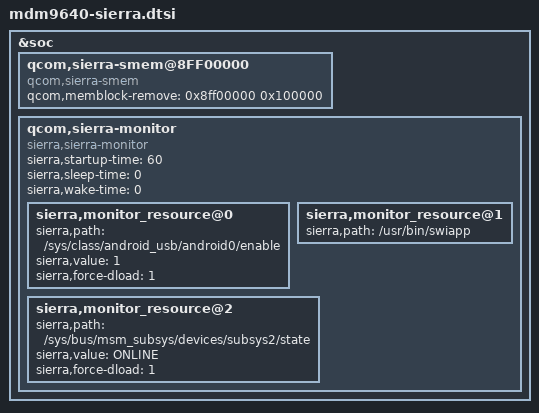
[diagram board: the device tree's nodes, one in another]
/* Copyright (c) 2015, Sierra Wireless, Inc. All rights reserved.
 *
 * This program is free software; you can redistribute it and/or modify
 * it under the terms of the GNU General Public License version 2 and
 * only version 2 as published by the Free Software Foundation.
 *
 * This program is distributed in the hope that it will be useful,
 * but WITHOUT ANY WARRANTY; without even the implied warranty of
 * MERCHANTABILITY or FITNESS FOR A PARTICULAR PURPOSE.  See the
 * GNU General Public License for more details.
 */

&soc {
/* Sierra shared memory
 *
 * A section of memory at the top of DDR is reserved for Sierra
 * boot-app messages, crash information, and other data.  This section
 * is non-initialized in order to preserve data across reboots.  The
 * size and base are (unfortunately) defined in multiple places.
 * 
 * WARNING:  These definitions must be kept in sync
 *
 * boot_images/build/ms/9x45.target.builds
 * modem_proc/config/9645/cust_config.xml
 * modem_proc/sierra/bs/api/bsaddress.h
 * apps_proc/kernel/arch/arm/mach-msm/include/mach/sierra_smem.h
 * apps_proc/kernel/arch/arm/boot/dts/qcom/mdm9640.dtsi
 */
	qcom,sierra-smem@8FF00000 {
		compatible = "qcom,sierra-smem";
		qcom,memblock-remove = <0x8ff00000 0x100000>;
	};


	qcom,sierra-monitor {
		compatible = "sierra,sierra-monitor";

		sierra,startup-time = <60>;
		sierra,sleep-time = <0>;
		sierra,wake-time = <0>;

		/* check if USB enabled */
		sierra,monitor_resource@0 {
			sierra,path = "/sys/class/android_usb/android0/enable";
			sierra,value = "1";
			sierra,force-dload = <1>;
		};

		/* check if swiapp exists */
		sierra,monitor_resource@1 {
			sierra,path = "/usr/bin/swiapp";
		};

		/* check if mpss is loaded */
		sierra,monitor_resource@2 {
			sierra,path = "/sys/bus/msm_subsys/devices/subsys2/state";
			sierra,value = "ONLINE";
			sierra,force-dload = <1>;
		};

	};
};

